# Espressif register map
File version: 1.0
CPU: Xtensa LX6 1, little endian, no MPU, FPU, 3 interrupt priority bits
Registers are 32-bit, access not given, reset 0x0 unless marked. A register's access mark holds for its fields unless they carry their own. Offsets are from the block's base; [hi:lo] are bit positions; {n}, {i} and the like mark numbered series.

## APB_CTRL
Base 0x3FF66000
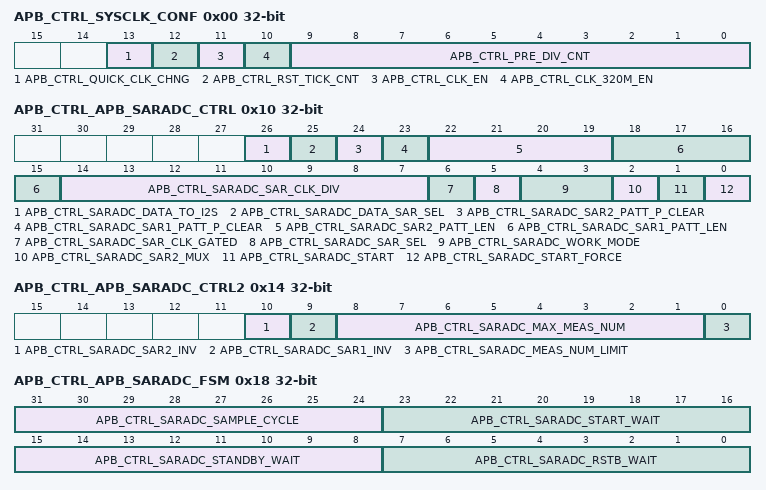
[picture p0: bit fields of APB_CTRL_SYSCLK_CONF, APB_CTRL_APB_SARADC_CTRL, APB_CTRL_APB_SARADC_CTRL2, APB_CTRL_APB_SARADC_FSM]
0x00 APB_CTRL_SYSCLK_CONF
  [13] APB_CTRL_QUICK_CLK_CHNG, [12] APB_CTRL_RST_TICK_CNT, [11] APB_CTRL_CLK_EN, [10] APB_CTRL_CLK_320M_EN, [9:0] APB_CTRL_PRE_DIV_CNT
0x04 APB_CTRL_XTAL_TICK_CONF
  [7:0] APB_CTRL_XTAL_TICK_NUM
0x08 APB_CTRL_PLL_TICK_CONF
  [7:0] APB_CTRL_PLL_TICK_NUM
0x0C APB_CTRL_CK8M_TICK_CONF
  [7:0] APB_CTRL_CK8M_TICK_NUM
0x10 APB_CTRL_APB_SARADC_CTRL
  [26] APB_CTRL_SARADC_DATA_TO_I2S, [25] APB_CTRL_SARADC_DATA_SAR_SEL, [24] APB_CTRL_SARADC_SAR2_PATT_P_CLEAR, [23] APB_CTRL_SARADC_SAR1_PATT_P_CLEAR, [22:19] APB_CTRL_SARADC_SAR2_PATT_LEN, [18:15] APB_CTRL_SARADC_SAR1_PATT_LEN, [14:7] APB_CTRL_SARADC_SAR_CLK_DIV, [6] APB_CTRL_SARADC_SAR_CLK_GATED, [5] APB_CTRL_SARADC_SAR_SEL, [4:3] APB_CTRL_SARADC_WORK_MODE, [2] APB_CTRL_SARADC_SAR2_MUX, [1] APB_CTRL_SARADC_START, [0] APB_CTRL_SARADC_START_FORCE
0x14 APB_CTRL_APB_SARADC_CTRL2
  [10] APB_CTRL_SARADC_SAR2_INV, [9] APB_CTRL_SARADC_SAR1_INV, [8:1] APB_CTRL_SARADC_MAX_MEAS_NUM, [0] APB_CTRL_SARADC_MEAS_NUM_LIMIT
0x18 APB_CTRL_APB_SARADC_FSM
  [31:24] APB_CTRL_SARADC_SAMPLE_CYCLE, [23:16] APB_CTRL_SARADC_START_WAIT, [15:8] APB_CTRL_SARADC_STANDBY_WAIT, [7:0] APB_CTRL_SARADC_RSTB_WAIT
{0x18+4i} APB_CTRL_APB_SARADC_SAR1_PATT_TAB{i} (i=1..4)
  [31:0] APB_CTRL_SARADC_SAR1_PATT_TAB{i}
{0x28+4i} APB_CTRL_APB_SARADC_SAR2_PATT_TAB{i} (i=1..4)
  [31:0] APB_CTRL_SARADC_SAR2_PATT_TAB{i}
0x3C APB_CTRL_APLL_TICK_CONF
  [7:0] APB_CTRL_APLL_TICK_NUM
0x7C APB_CTRL_DATE

## SYSCON
Base 0x3FF66000
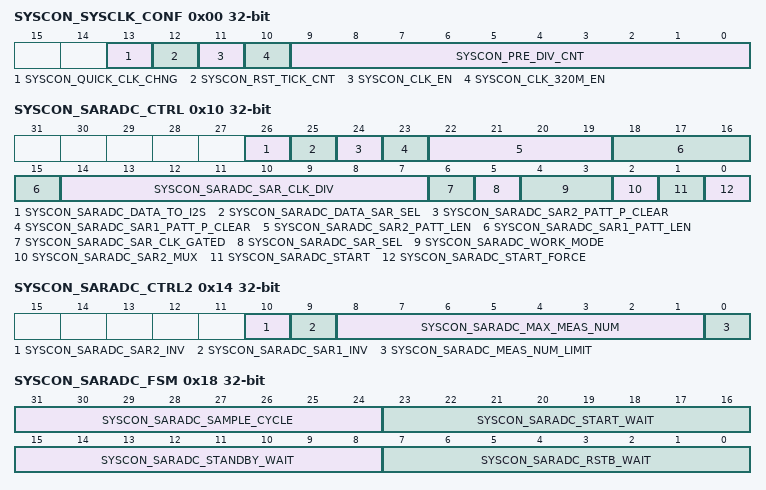
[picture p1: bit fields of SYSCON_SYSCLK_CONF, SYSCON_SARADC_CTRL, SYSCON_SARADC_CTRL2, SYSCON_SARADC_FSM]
0x00 SYSCON_SYSCLK_CONF
  [13] SYSCON_QUICK_CLK_CHNG, [12] SYSCON_RST_TICK_CNT, [11] SYSCON_CLK_EN, [10] SYSCON_CLK_320M_EN, [9:0] SYSCON_PRE_DIV_CNT
0x04 SYSCON_XTAL_TICK_CONF
  [7:0] SYSCON_XTAL_TICK_NUM
0x08 SYSCON_PLL_TICK_CONF
  [7:0] SYSCON_PLL_TICK_NUM
0x0C SYSCON_CK8M_TICK_CONF
  [7:0] SYSCON_CK8M_TICK_NUM
0x10 SYSCON_SARADC_CTRL
  [26] SYSCON_SARADC_DATA_TO_I2S, [25] SYSCON_SARADC_DATA_SAR_SEL, [24] SYSCON_SARADC_SAR2_PATT_P_CLEAR, [23] SYSCON_SARADC_SAR1_PATT_P_CLEAR, [22:19] SYSCON_SARADC_SAR2_PATT_LEN, [18:15] SYSCON_SARADC_SAR1_PATT_LEN, [14:7] SYSCON_SARADC_SAR_CLK_DIV, [6] SYSCON_SARADC_SAR_CLK_GATED, [5] SYSCON_SARADC_SAR_SEL, [4:3] SYSCON_SARADC_WORK_MODE, [2] SYSCON_SARADC_SAR2_MUX, [1] SYSCON_SARADC_START, [0] SYSCON_SARADC_START_FORCE
0x14 SYSCON_SARADC_CTRL2
  [10] SYSCON_SARADC_SAR2_INV, [9] SYSCON_SARADC_SAR1_INV, [8:1] SYSCON_SARADC_MAX_MEAS_NUM, [0] SYSCON_SARADC_MEAS_NUM_LIMIT
0x18 SYSCON_SARADC_FSM
  [31:24] SYSCON_SARADC_SAMPLE_CYCLE, [23:16] SYSCON_SARADC_START_WAIT, [15:8] SYSCON_SARADC_STANDBY_WAIT, [7:0] SYSCON_SARADC_RSTB_WAIT
{0x18+4i} SYSCON_SARADC_SAR1_PATT_TAB{i} (i=1..4)
{0x28+4i} SYSCON_SARADC_SAR2_PATT_TAB{i} (i=1..4)
0x3C SYSCON_APLL_TICK_CONF
  [7:0] SYSCON_APLL_TICK_NUM
0x7C SYSCON_DATE

## RTC_I2C
Base 0x3FF48C00
0x00 RTC_I2C_SCL_LOW_PERIOD
  [18:0] RTC_I2C_SCL_LOW_PERIOD
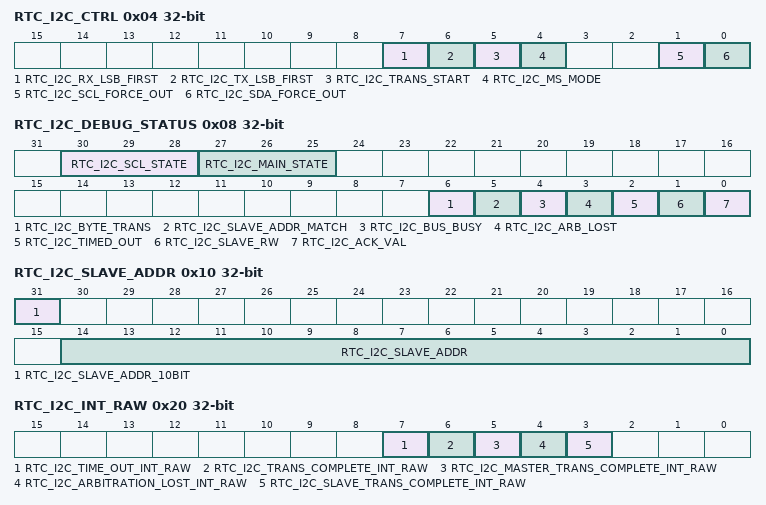
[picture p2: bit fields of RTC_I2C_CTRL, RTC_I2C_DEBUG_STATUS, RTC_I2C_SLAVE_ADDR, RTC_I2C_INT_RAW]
0x04 RTC_I2C_CTRL
  [7] RTC_I2C_RX_LSB_FIRST, [6] RTC_I2C_TX_LSB_FIRST, [5] RTC_I2C_TRANS_START, [4] RTC_I2C_MS_MODE, [1] RTC_I2C_SCL_FORCE_OUT, [0] RTC_I2C_SDA_FORCE_OUT
0x08 RTC_I2C_DEBUG_STATUS
  [30:28] RTC_I2C_SCL_STATE, [27:25] RTC_I2C_MAIN_STATE, [6] RTC_I2C_BYTE_TRANS, [5] RTC_I2C_SLAVE_ADDR_MATCH, [4] RTC_I2C_BUS_BUSY, [3] RTC_I2C_ARB_LOST, [2] RTC_I2C_TIMED_OUT, [1] RTC_I2C_SLAVE_RW, [0] RTC_I2C_ACK_VAL
0x0C RTC_I2C_TIMEOUT
  [19:0] RTC_I2C_TIMEOUT
0x10 RTC_I2C_SLAVE_ADDR
  [31] RTC_I2C_SLAVE_ADDR_10BIT, [14:0] RTC_I2C_SLAVE_ADDR
0x20 RTC_I2C_INT_RAW
  [7] RTC_I2C_TIME_OUT_INT_RAW, [6] RTC_I2C_TRANS_COMPLETE_INT_RAW, [5] RTC_I2C_MASTER_TRANS_COMPLETE_INT_RAW, [4] RTC_I2C_ARBITRATION_LOST_INT_RAW, [3] RTC_I2C_SLAVE_TRANS_COMPLETE_INT_RAW
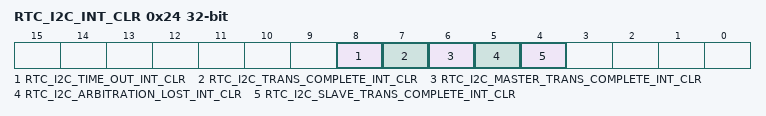
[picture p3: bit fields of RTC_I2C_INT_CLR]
0x24 RTC_I2C_INT_CLR
  [8] RTC_I2C_TIME_OUT_INT_CLR, [7] RTC_I2C_TRANS_COMPLETE_INT_CLR, [6] RTC_I2C_MASTER_TRANS_COMPLETE_INT_CLR, [5] RTC_I2C_ARBITRATION_LOST_INT_CLR, [4] RTC_I2C_SLAVE_TRANS_COMPLETE_INT_CLR
0x30 RTC_I2C_SDA_DUTY
  [19:0] RTC_I2C_SDA_DUTY
0x38 RTC_I2C_SCL_HIGH_PERIOD
  [19:0] RTC_I2C_SCL_HIGH_PERIOD
0x40 RTC_I2C_SCL_START_PERIOD
  [19:0] RTC_I2C_SCL_START_PERIOD
0x44 RTC_I2C_SCL_STOP_PERIOD
  [19:0] RTC_I2C_SCL_STOP_PERIOD

## LEDC
Base 0x3FF59000
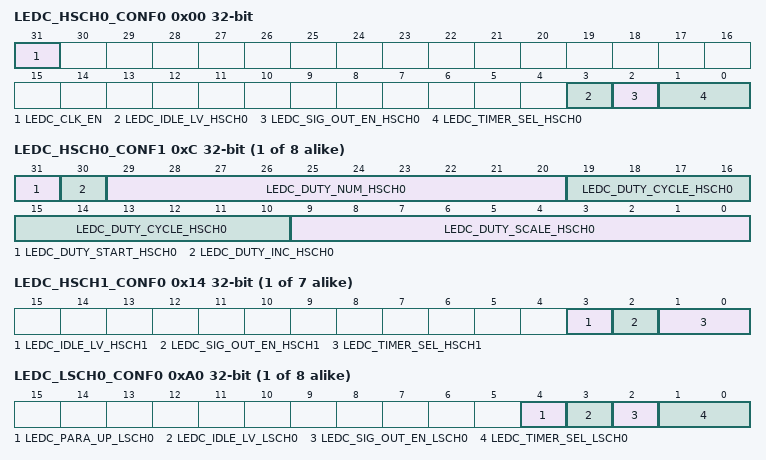
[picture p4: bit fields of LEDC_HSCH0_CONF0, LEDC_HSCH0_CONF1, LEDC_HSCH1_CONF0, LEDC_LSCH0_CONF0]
0x00 LEDC_HSCH0_CONF0
  [31] LEDC_CLK_EN, [3] LEDC_IDLE_LV_HSCH0, [2] LEDC_SIG_OUT_EN_HSCH0, [1:0] LEDC_TIMER_SEL_HSCH0
{0x4+0x14*i} LEDC_HSCH{i}_HPOINT (i=0..7)
  [19:0] LEDC_HPOINT_HSCH{i}
{0x8+0x14*i} LEDC_HSCH{i}_DUTY (i=0..7)
  [24:0] LEDC_DUTY_HSCH{i}
{0xC+0x14*i} LEDC_HSCH{i}_CONF1 (i=0..7)
  [31] LEDC_DUTY_START_HSCH{i}, [30] LEDC_DUTY_INC_HSCH{i}, [29:20] LEDC_DUTY_NUM_HSCH{i}, [19:10] LEDC_DUTY_CYCLE_HSCH{i}, [9:0] LEDC_DUTY_SCALE_HSCH{i}
{0x10+0x14*i} LEDC_HSCH{i}_DUTY_R (i=0..7)
  [24:0] LEDC_DUTY_HSCH{i}
{0x0+0x14*i} LEDC_HSCH{i}_CONF0 (i=1..7)
  [3] LEDC_IDLE_LV_HSCH{i}, [2] LEDC_SIG_OUT_EN_HSCH{i}, [1:0] LEDC_TIMER_SEL_HSCH{i}
{0xA0+0x14*i} LEDC_LSCH{i}_CONF0 (i=0..7)
  [4] LEDC_PARA_UP_LSCH{i}, [3] LEDC_IDLE_LV_LSCH{i}, [2] LEDC_SIG_OUT_EN_LSCH{i}, [1:0] LEDC_TIMER_SEL_LSCH{i}
{0xA4+0x14*i} LEDC_LSCH{i}_HPOINT (i=0..7)
  [19:0] LEDC_HPOINT_LSCH{i}
{0xA8+0x14*i} LEDC_LSCH{i}_DUTY (i=0..7)
  [24:0] LEDC_DUTY_LSCH{i}
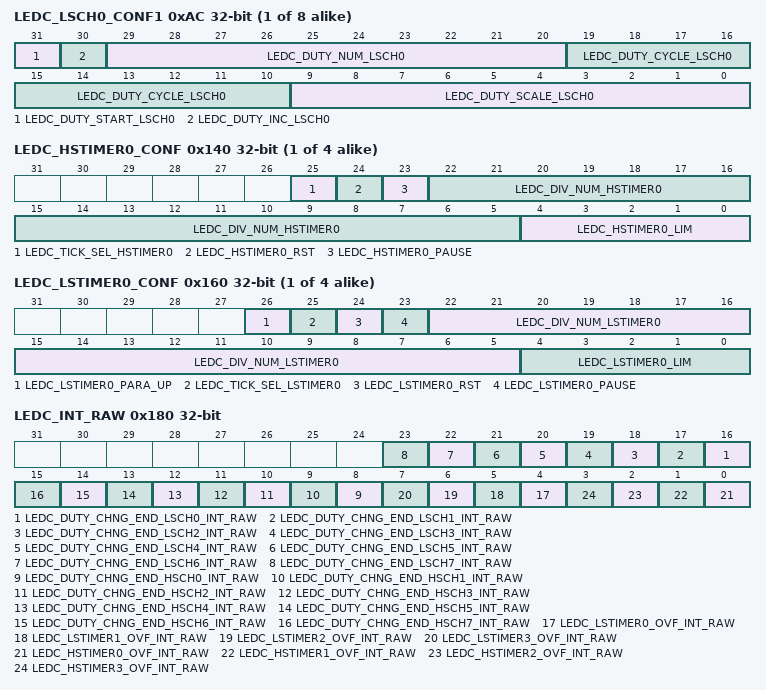
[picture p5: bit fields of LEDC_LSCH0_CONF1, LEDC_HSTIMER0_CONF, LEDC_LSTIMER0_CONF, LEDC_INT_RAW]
{0xAC+0x14*i} LEDC_LSCH{i}_CONF1 (i=0..7)
  [31] LEDC_DUTY_START_LSCH{i}, [30] LEDC_DUTY_INC_LSCH{i}, [29:20] LEDC_DUTY_NUM_LSCH{i}, [19:10] LEDC_DUTY_CYCLE_LSCH{i}, [9:0] LEDC_DUTY_SCALE_LSCH{i}
{0xB0+0x14*i} LEDC_LSCH{i}_DUTY_R (i=0..7)
  [24:0] LEDC_DUTY_LSCH{i}
{0x140+8i} LEDC_HSTIMER{i}_CONF (i=0..3)
  [25] LEDC_TICK_SEL_HSTIMER{i}, [24] LEDC_HSTIMER{i}_RST, [23] LEDC_HSTIMER{i}_PAUSE, [22:5] LEDC_DIV_NUM_HSTIMER{i}, [4:0] LEDC_HSTIMER{i}_LIM
{0x144+8i} LEDC_HSTIMER{i}_VALUE (i=0..3)
  [19:0] LEDC_HSTIMER{i}_CNT
{0x160+8i} LEDC_LSTIMER{i}_CONF (i=0..3)
  [26] LEDC_LSTIMER{i}_PARA_UP, [25] LEDC_TICK_SEL_LSTIMER{i}, [24] LEDC_LSTIMER{i}_RST, [23] LEDC_LSTIMER{i}_PAUSE, [22:5] LEDC_DIV_NUM_LSTIMER{i}, [4:0] LEDC_LSTIMER{i}_LIM
{0x164+8i} LEDC_LSTIMER{i}_VALUE (i=0..3)
  [19:0] LEDC_LSTIMER{i}_CNT
0x180 LEDC_INT_RAW
  [n+16] LEDC_DUTY_CHNG_END_LSCH{n}_INT_RAW (n=0..7), [n+8] LEDC_DUTY_CHNG_END_HSCH{n}_INT_RAW (n=0..7), [n+4] LEDC_LSTIMER{n}_OVF_INT_RAW (n=0..3), [n] LEDC_HSTIMER{n}_OVF_INT_RAW (n=0..3)
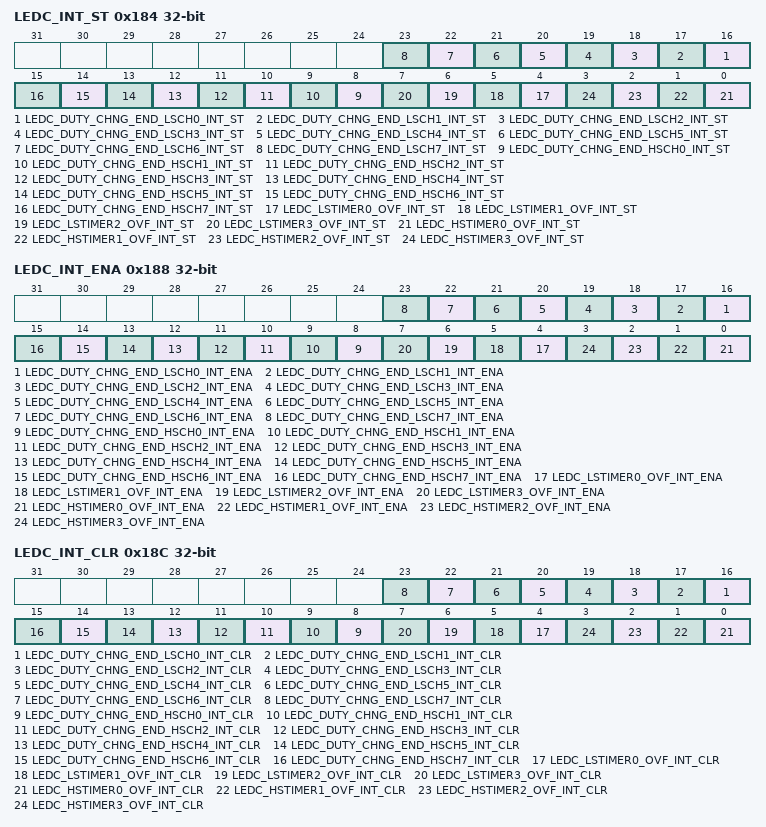
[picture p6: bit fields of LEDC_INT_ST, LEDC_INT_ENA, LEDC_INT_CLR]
0x184 LEDC_INT_ST
  [n+16] LEDC_DUTY_CHNG_END_LSCH{n}_INT_ST (n=0..7), [n+8] LEDC_DUTY_CHNG_END_HSCH{n}_INT_ST (n=0..7), [n+4] LEDC_LSTIMER{n}_OVF_INT_ST (n=0..3), [n] LEDC_HSTIMER{n}_OVF_INT_ST (n=0..3)
0x188 LEDC_INT_ENA
  [n+16] LEDC_DUTY_CHNG_END_LSCH{n}_INT_ENA (n=0..7), [n+8] LEDC_DUTY_CHNG_END_HSCH{n}_INT_ENA (n=0..7), [n+4] LEDC_LSTIMER{n}_OVF_INT_ENA (n=0..3), [n] LEDC_HSTIMER{n}_OVF_INT_ENA (n=0..3)
0x18C LEDC_INT_CLR
  [n+16] LEDC_DUTY_CHNG_END_LSCH{n}_INT_CLR (n=0..7), [n+8] LEDC_DUTY_CHNG_END_HSCH{n}_INT_CLR (n=0..7), [n+4] LEDC_LSTIMER{n}_OVF_INT_CLR (n=0..3), [n] LEDC_HSTIMER{n}_OVF_INT_CLR (n=0..3)
0x190 LEDC_CONF
  [0] LEDC_APB_CLK_SEL
0x1FC LEDC_DATE
